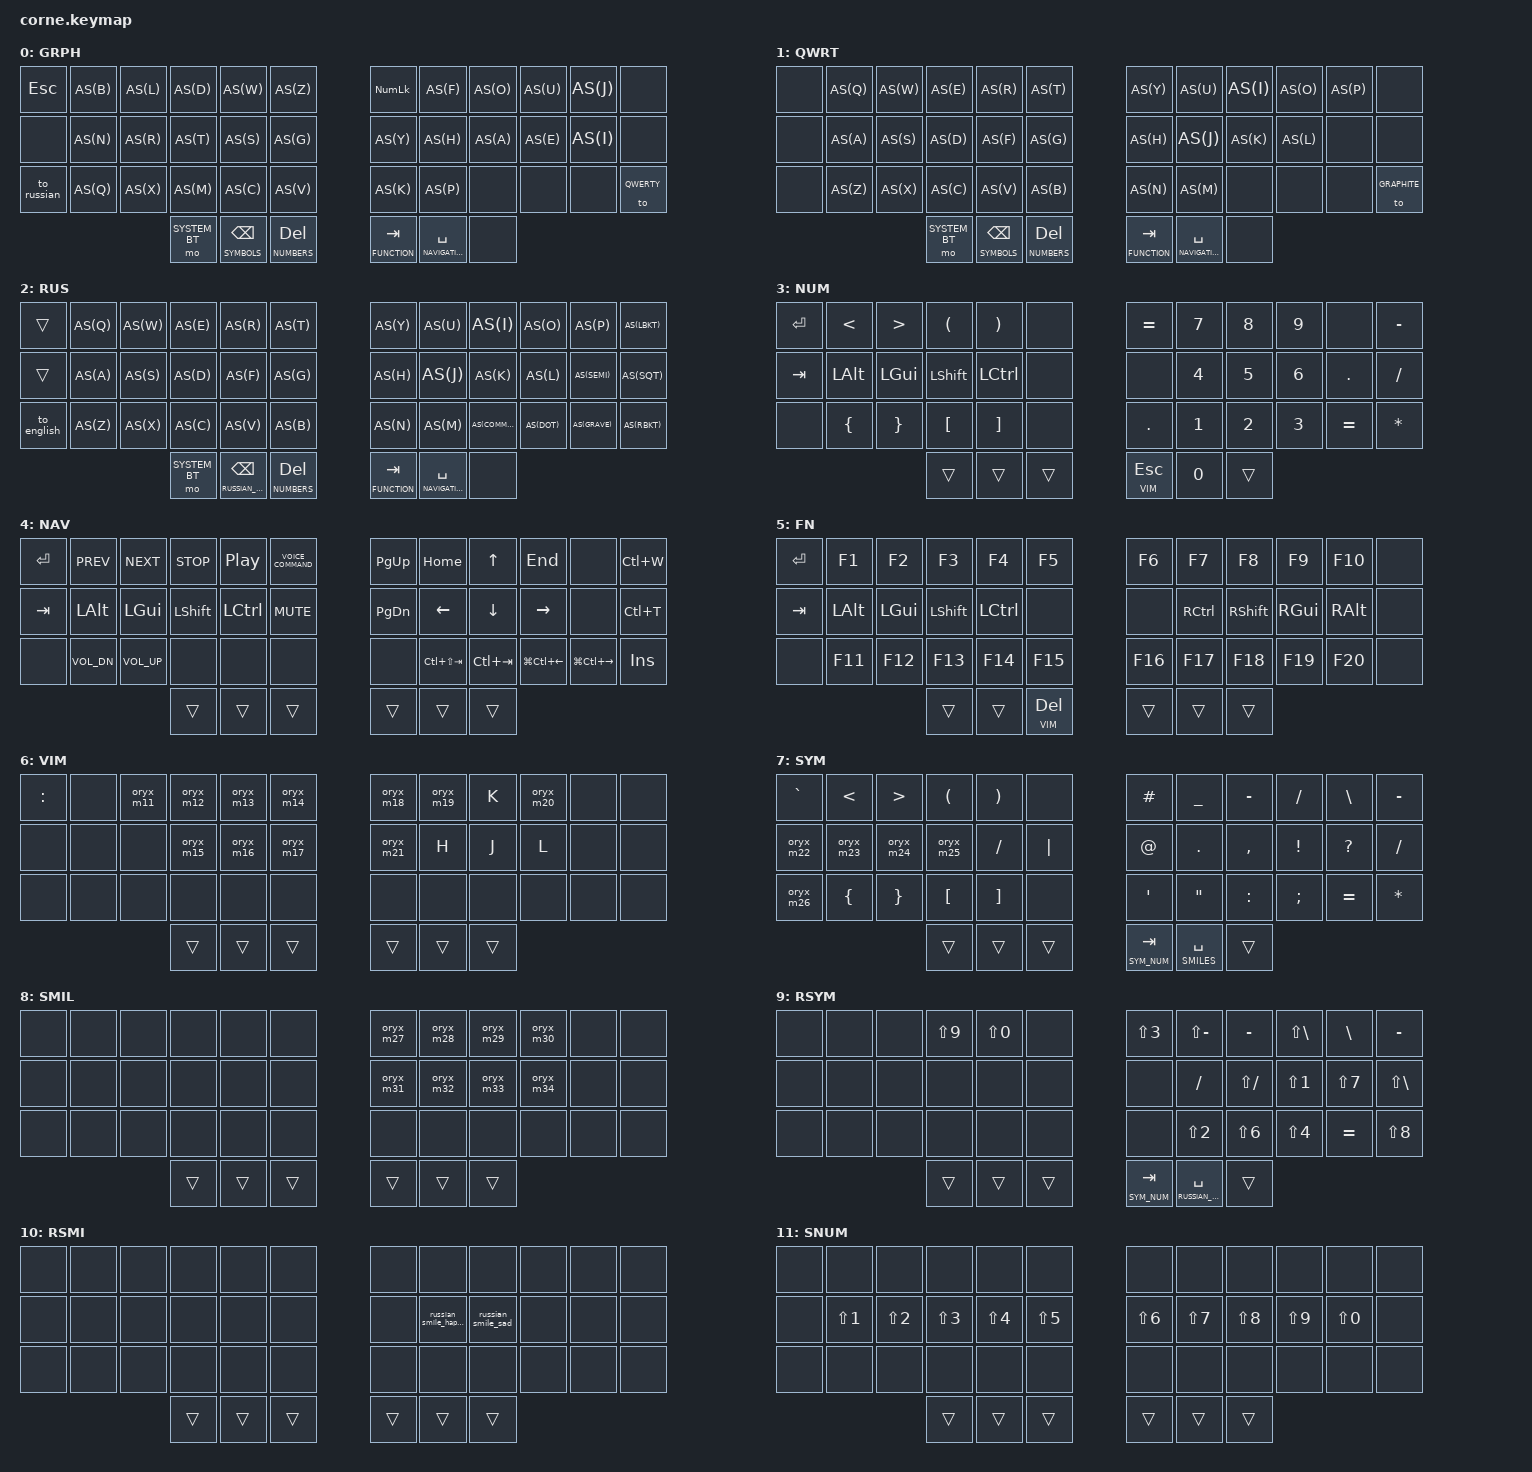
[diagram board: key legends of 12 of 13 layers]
/*
 * Copyright (c) 2020 The ZMK Contributors
 *
 * SPDX-License-Identifier: MIT
 */

#include <behaviors.dtsi>
#include <behaviors/os_profile.dtsi>
#include <dt-bindings/zmk/keys.h>
#include <dt-bindings/zmk/bt.h>
#include <dt-bindings/tpak/os_profile.h>

#define GRAPHITE 0
#define QWERTY 1
#define RUSSIAN 2
#define NUMBERS 3
#define NAVIGATION 4
#define FUNCTION 5
#define VIM 6
#define SYMBOLS 7
#define SMILES 8
#define RUSSIAN_SYMBOLS 9
#define RUSSIAN_SMILES 10
#define SYM_NUM 11
#define SYSTEM_BT 12

// Tap a letter normally; hold it for 300 ms to send Left Shift + letter.
#define AS(keycode) &as LS(keycode) keycode

// Match QMK quick-tap repeat behavior for layer-tap keys.
&lt {
        quick-tap-ms = <250>;
};

// Keep Caps Word active across Russian-PC punctuation-backed letters.
// ZMK only auto-shifts HID A-Z, so RU_HA, RU_HARD, RU_ZHE, RU_E, RU_BE, RU_YU, and RU_YO remain lowercase until a custom behavior is added.
&caps_word {
        continue-list = <UNDERSCORE BACKSPACE DELETE LBKT RBKT SEMI SQT COMMA DOT GRAVE>;
};

/ {
        behaviors {
                as: auto_shift {
                        compatible = "zmk,behavior-hold-tap";
                        #binding-cells = <2>;
                        tapping-term-ms = <300>;
                        quick-tap-ms = <0>;
                        flavor = "tap-preferred";
                        bindings = <&kp>, <&kp>;
                        display-name = "Auto Shift";
                };

                bt_clear_hold: bt_clear_hold {
                        compatible = "zmk,behavior-hold-tap";
                        #binding-cells = <2>;
                        tapping-term-ms = <1500>;
                        quick-tap-ms = <0>;
                        flavor = "tap-preferred";
                        bindings = <&bt_clear_macro>, <&none>;
                        display-name = "Hold to Clear Bluetooth";
                };
        };

        macros {
                // Select Russian-PC on the host with Ctrl+Shift+2, then activate the Russian base layer.
                to_russian: to_russian {
                        compatible = "zmk,behavior-macro";
                        #binding-cells = <0>;
                        wait-ms = <40>;
                        tap-ms = <40>;
                        bindings = <&kp LC(LS(N2)) &to RUSSIAN>;
                };

                // Select English on the host with Ctrl+Shift+1, then return to the Graphite base layer.
                to_english: to_english {
                        compatible = "zmk,behavior-macro";
                        #binding-cells = <0>;
                        wait-ms = <40>;
                        tap-ms = <40>;
                        bindings = <&kp LC(LS(N1)) &to GRAPHITE>;
                };

                // Clears the active Bluetooth profile; invoked only after a protected hold.
                bt_clear_macro: bt_clear_macro {
                        compatible = "zmk,behavior-macro";
                        #binding-cells = <0>;
                        wait-ms = <0>;
                        tap-ms = <0>;
                        bindings = <&bt BT_CLR>;
                };

                // Types "  e" (Space, Space, E).
                oryx_m11: oryx_m11 {
                        compatible = "zmk,behavior-macro";
                        #binding-cells = <0>;
                        wait-ms = <40>;
                        tap-ms = <40>;
                        bindings = <&kp SPACE &kp SPACE &kp E>;
                };

                // Vim: force quit without saving (Esc, :q!, Enter).
                oryx_m12: oryx_m12 {
                        compatible = "zmk,behavior-macro";
                        #binding-cells = <0>;
                        wait-ms = <40>;
                        tap-ms = <40>;
                        bindings = <&kp ESC &kp COLON &kp Q &kp EXCL &kp RET>;
                };

                // Vim: write the current file (Esc, :w, Enter).
                oryx_m13: oryx_m13 {
                        compatible = "zmk,behavior-macro";
                        #binding-cells = <0>;
                        wait-ms = <40>;
                        tap-ms = <40>;
                        bindings = <&kp ESC &kp COLON &kp W &kp RET>;
                };

                // Types " gg" (Space, G, G).
                oryx_m14: oryx_m14 {
                        compatible = "zmk,behavior-macro";
                        #binding-cells = <0>;
                        wait-ms = <40>;
                        tap-ms = <40>;
                        bindings = <&kp SPACE &kp G &kp G>;
                };

                // Vim: quit the current window (Esc, :q, Enter).
                oryx_m15: oryx_m15 {
                        compatible = "zmk,behavior-macro";
                        #binding-cells = <0>;
                        wait-ms = <40>;
                        tap-ms = <40>;
                        bindings = <&kp ESC &kp COLON &kp Q &kp RET>;
                };

                // Vim: write and quit (Esc, :wq, Enter).
                oryx_m16: oryx_m16 {
                        compatible = "zmk,behavior-macro";
                        #binding-cells = <0>;
                        wait-ms = <40>;
                        tap-ms = <40>;
                        bindings = <&kp ESC &kp COLON &kp W &kp Q &kp RET>;
                };

                // Types " tb" (Space, T, B).
                oryx_m17: oryx_m17 {
                        compatible = "zmk,behavior-macro";
                        #binding-cells = <0>;
                        wait-ms = <40>;
                        tap-ms = <40>;
                        bindings = <&kp SPACE &kp T &kp B>;
                };

                // Vim: close the current window (Ctrl-W, q).
                oryx_m18: oryx_m18 {
                        compatible = "zmk,behavior-macro";
                        #binding-cells = <0>;
                        wait-ms = <40>;
                        tap-ms = <40>;
                        bindings = <&kp LC(W) &kp Q>;
                };

                // Vim: create a horizontal split (Esc, :sp, Enter).
                oryx_m19: oryx_m19 {
                        compatible = "zmk,behavior-macro";
                        #binding-cells = <0>;
                        wait-ms = <40>;
                        tap-ms = <40>;
                        bindings = <&kp ESC &kp COLON &kp S &kp P &kp RET>;
                };

                // Vim: create a vertical split (Esc, :vsp, Enter).
                oryx_m20: oryx_m20 {
                        compatible = "zmk,behavior-macro";
                        #binding-cells = <0>;
                        wait-ms = <40>;
                        tap-ms = <40>;
                        bindings = <&kp ESC &kp COLON &kp V &kp S &kp P &kp RET>;
                };

                // Vim: send the window-command prefix (Ctrl-W).
                oryx_m21: oryx_m21 {
                        compatible = "zmk,behavior-macro";
                        #binding-cells = <0>;
                        wait-ms = <40>;
                        tap-ms = <40>;
                        bindings = <&kp LC(W)>;
                };

                // Types ". ~/".
                oryx_m22: oryx_m22 {
                        compatible = "zmk,behavior-macro";
                        #binding-cells = <0>;
                        wait-ms = <40>;
                        tap-ms = <40>;
                        bindings = <&kp DOT &kp SPACE &kp TILDE &kp FSLH>;
                };

                // Types "~/".
                oryx_m23: oryx_m23 {
                        compatible = "zmk,behavior-macro";
                        #binding-cells = <0>;
                        wait-ms = <40>;
                        tap-ms = <40>;
                        bindings = <&kp TILDE &kp FSLH>;
                };

                // Types "../".
                oryx_m24: oryx_m24 {
                        compatible = "zmk,behavior-macro";
                        #binding-cells = <0>;
                        wait-ms = <40>;
                        tap-ms = <40>;
                        bindings = <&kp DOT &kp DOT &kp FSLH>;
                };

                // Types "./".
                oryx_m25: oryx_m25 {
                        compatible = "zmk,behavior-macro";
                        #binding-cells = <0>;
                        wait-ms = <40>;
                        tap-ms = <40>;
                        bindings = <&kp DOT &kp FSLH>;
                };

                // Types ". ./".
                oryx_m26: oryx_m26 {
                        compatible = "zmk,behavior-macro";
                        #binding-cells = <0>;
                        wait-ms = <40>;
                        tap-ms = <40>;
                        bindings = <&kp DOT &kp SPACE &kp DOT &kp FSLH>;
                };

                // Types "8-O".
                oryx_m27: oryx_m27 {
                        compatible = "zmk,behavior-macro";
                        #binding-cells = <0>;
                        wait-ms = <40>;
                        tap-ms = <40>;
                        bindings = <&kp N8 &kp MINUS &kp LS(O)>;
                };

                // Types ":-|".
                oryx_m28: oryx_m28 {
                        compatible = "zmk,behavior-macro";
                        #binding-cells = <0>;
                        wait-ms = <40>;
                        tap-ms = <40>;
                        bindings = <&kp COLON &kp MINUS &kp PIPE>;
                };

                // Types colon, minus, and backslash.
                oryx_m29: oryx_m29 {
                        compatible = "zmk,behavior-macro";
                        #binding-cells = <0>;
                        wait-ms = <40>;
                        tap-ms = <40>;
                        bindings = <&kp COLON &kp MINUS &kp BSLH>;
                };

                // Types ":`[".
                oryx_m30: oryx_m30 {
                        compatible = "zmk,behavior-macro";
                        #binding-cells = <0>;
                        wait-ms = <40>;
                        tap-ms = <40>;
                        bindings = <&kp COLON &kp GRAVE &kp LBKT>;
                };

                // Types ":D".
                oryx_m31: oryx_m31 {
                        compatible = "zmk,behavior-macro";
                        #binding-cells = <0>;
                        wait-ms = <40>;
                        tap-ms = <40>;
                        bindings = <&kp COLON &kp LS(D)>;
                };

                // Types ":)".
                oryx_m32: oryx_m32 {
                        compatible = "zmk,behavior-macro";
                        #binding-cells = <0>;
                        wait-ms = <40>;
                        tap-ms = <40>;
                        bindings = <&kp COLON &kp RPAR>;
                };

                // Types ":(".
                oryx_m33: oryx_m33 {
                        compatible = "zmk,behavior-macro";
                        #binding-cells = <0>;
                        wait-ms = <40>;
                        tap-ms = <40>;
                        bindings = <&kp COLON &kp LPAR>;
                };

                // Types ":-E".
                oryx_m34: oryx_m34 {
                        compatible = "zmk,behavior-macro";
                        #binding-cells = <0>;
                        wait-ms = <40>;
                        tap-ms = <40>;
                        bindings = <&kp COLON &kp MINUS &kp LS(E)>;
                };

                // Russian-PC smile from Oryx ST_MACRO_35: types ":)" with Shift+6, Shift+0.
                russian_smile_happy: russian_smile_happy {
                        compatible = "zmk,behavior-macro";
                        #binding-cells = <0>;
                        wait-ms = <10>;
                        tap-ms = <10>;
                        bindings = <&kp LS(N6) &kp LS(N0)>;
                };

                // Russian-PC sad smile from Oryx ST_MACRO_36: types ":(" with Shift+6, Shift+9.
                russian_smile_sad: russian_smile_sad {
                        compatible = "zmk,behavior-macro";
                        #binding-cells = <0>;
                        wait-ms = <10>;
                        tap-ms = <10>;
                        bindings = <&kp LS(N6) &kp LS(N9)>;
                };
        };

        combos {
                compatible = "zmk,combos";

                // Graphite F+O+U: select Russian-PC on the host and activate the Russian layer.
                to_russian_combo {
                        timeout-ms = <50>;
                        key-positions = <7 8 9>;
                        bindings = <&to_russian>;
                        layers = <GRAPHITE>;
                };

                // Russian RU_GHE+RU_SHA+RU_SHCH: select English on the host and return to Graphite.
                to_english_combo {
                        timeout-ms = <50>;
                        key-positions = <7 8 9>;
                        bindings = <&to_english>;
                        layers = <RUSSIAN>;
                };

                enter_combo {
                        timeout-ms = <50>;
                        key-positions = <19 20 21>;
                        bindings = <&kp RET>;
                        layers = <GRAPHITE QWERTY RUSSIAN>;
                };

                tab_combo {
                        timeout-ms = <50>;
                        key-positions = <14 15 16>;
                        bindings = <&kp TAB>;
                        layers = <GRAPHITE QWERTY RUSSIAN>;
                };

                // Oryx N+S: toggle Caps Word on the base layer.
                caps_word_combo {
                        timeout-ms = <50>;
                        key-positions = <13 16>;
                        bindings = <&caps_word>;
                        layers = <GRAPHITE QWERTY RUSSIAN>;
                };

                // Oryx N+G: toggle Caps Lock on the base layer.
                caps_lock_combo {
                        timeout-ms = <50>;
                        key-positions = <13 17>;
                        bindings = <&kp CAPSLOCK>;
                        layers = <GRAPHITE QWERTY RUSSIAN>;
                };

                // Oryx 7+8+9: type minus on the Numbers layer.
                numbers_minus_combo {
                        timeout-ms = <50>;
                        key-positions = <7 8 9>;
                        bindings = <&kp MINUS>;
                        layers = <NUMBERS>;
                };

                // Oryx 4+5+6: type equals on the Numbers layer.
                numbers_equal_combo {
                        timeout-ms = <50>;
                        key-positions = <19 20 21>;
                        bindings = <&kp EQUAL>;
                        layers = <NUMBERS>;
                };

                // Oryx 1+2+3: type plus on the Numbers layer.
                numbers_plus_combo {
                        timeout-ms = <50>;
                        key-positions = <31 32 33>;
                        bindings = <&kp PLUS>;
                        layers = <NUMBERS>;
                };

                // Oryx 4+5+6+Dot: type slash on the Numbers layer.
                numbers_slash_combo {
                        timeout-ms = <80>;
                        key-positions = <19 20 21 22>;
                        bindings = <&kp FSLH>;
                        layers = <NUMBERS>;
                };

                // Oryx 1+2+3+Equal: type asterisk on the Numbers layer.
                numbers_asterisk_combo {
                        timeout-ms = <80>;
                        key-positions = <31 32 33 34>;
                        bindings = <&kp ASTRK>;
                        layers = <NUMBERS>;
                };

                // Oryx G+Z: hold the English Smiles layer.
                smiles_layer_combo {
                        timeout-ms = <50>;
                        key-positions = <5 17>;
                        bindings = <&mo SMILES>;
                        layers = <GRAPHITE QWERTY>;
                        slow-release;
                };

                // Oryx Russian RU_PE+RU_IE: hold the Russian Smiles layer.
                russian_smiles_layer_combo {
                        timeout-ms = <50>;
                        key-positions = <5 17>;
                        bindings = <&mo RUSSIAN_SMILES>;
                        layers = <RUSSIAN>;
                        slow-release;
                };

                // Oryx H+I: activate the Vim layer for one keypress.
                vim_layer_combo {
                        timeout-ms = <50>;
                        key-positions = <19 22>;
                        bindings = <&sl VIM>;
                        layers = <GRAPHITE QWERTY>;
                };

                // Oryx Q+N: hold Left Alt.
                left_alt_combo {
                        timeout-ms = <50>;
                        key-positions = <13 25>;
                        bindings = <&kp LALT>;
                        layers = <GRAPHITE QWERTY RUSSIAN>;
                        slow-release;
                };

                // Oryx X+R: hold Left GUI.
                left_gui_combo {
                        timeout-ms = <50>;
                        key-positions = <14 26>;
                        bindings = <&kp LGUI>;
                        layers = <GRAPHITE QWERTY RUSSIAN>;
                        slow-release;
                };

                // Oryx M+T: hold Left Shift.
                left_shift_combo {
                        timeout-ms = <50>;
                        key-positions = <15 27>;
                        bindings = <&kp LSHIFT>;
                        layers = <GRAPHITE QWERTY RUSSIAN>;
                        slow-release;
                };

                // Oryx C+S: hold Left Control.
                left_ctrl_combo {
                        timeout-ms = <50>;
                        key-positions = <16 28>;
                        bindings = <&kp LCTRL>;
                        layers = <GRAPHITE QWERTY RUSSIAN>;
                        slow-release;
                };

                // Oryx P+H: hold Right Control.
                right_ctrl_combo {
                        timeout-ms = <50>;
                        key-positions = <19 31>;
                        bindings = <&kp RCTRL>;
                        layers = <GRAPHITE QWERTY RUSSIAN>;
                        slow-release;
                };

                // Oryx F22+A: hold Right Shift.
                right_shift_combo {
                        timeout-ms = <50>;
                        key-positions = <20 32>;
                        bindings = <&kp RSHIFT>;
                        layers = <GRAPHITE QWERTY RUSSIAN>;
                        slow-release;
                };

                // Oryx F23+E: hold Right GUI.
                right_gui_combo {
                        timeout-ms = <50>;
                        key-positions = <21 33>;
                        bindings = <&kp RGUI>;
                        layers = <GRAPHITE QWERTY RUSSIAN>;
                        slow-release;
                };

                // Oryx F24+I: hold Right Alt.
                right_alt_combo {
                        timeout-ms = <50>;
                        key-positions = <22 34>;
                        bindings = <&kp RALT>;
                        layers = <GRAPHITE QWERTY RUSSIAN>;
                        slow-release;
                };

                // Oryx R+L: OS-aware Copy.
                copy_combo {
                        timeout-ms = <50>;
                        key-positions = <2 14>;
                        bindings = <&os_action OS_ACTION_COPY>;
                        layers = <GRAPHITE QWERTY RUSSIAN>;
                };

                // Oryx T+D: OS-aware Paste.
                paste_combo {
                        timeout-ms = <50>;
                        key-positions = <3 15>;
                        bindings = <&os_action OS_ACTION_PASTE>;
                        layers = <GRAPHITE QWERTY RUSSIAN>;
                };

                // Oryx R+L+T+D: OS-aware Cut.
                cut_combo {
                        timeout-ms = <80>;
                        key-positions = <2 3 14 15>;
                        bindings = <&os_action OS_ACTION_CUT>;
                        layers = <GRAPHITE QWERTY RUSSIAN>;
                };

                // Oryx A+O: OS-aware Undo.
                undo_combo {
                        timeout-ms = <50>;
                        key-positions = <8 20>;
                        bindings = <&os_action OS_ACTION_UNDO>;
                        layers = <GRAPHITE QWERTY RUSSIAN>;
                };

                // Oryx E+U: OS-aware Redo.
                redo_combo {
                        timeout-ms = <50>;
                        key-positions = <9 21>;
                        bindings = <&os_action OS_ACTION_REDO>;
                        layers = <GRAPHITE QWERTY RUSSIAN>;
                };

                // Oryx Y+H+A: OS-aware voice command.
                voice_combo {
                        timeout-ms = <50>;
                        key-positions = <18 19 20>;
                        bindings = <&os_action OS_ACTION_VOICE>;
                        layers = <GRAPHITE QWERTY RUSSIAN>;
                };

                // Oryx N+R+T: OS-aware deletion of the previous word.
                word_backspace_combo {
                        timeout-ms = <50>;
                        key-positions = <13 14 15>;
                        bindings = <&os_action OS_ACTION_WORD_BACKSPACE>;
                        layers = <GRAPHITE QWERTY RUSSIAN>;
                };

                // Oryx A+E+I: OS-aware deletion of the next word.
                word_delete_combo {
                        timeout-ms = <50>;
                        key-positions = <20 21 22>;
                        bindings = <&os_action OS_ACTION_WORD_DELETE>;
                        layers = <GRAPHITE QWERTY RUSSIAN>;
                };

                // Oryx Q+X+M: OS-aware movement to the previous word.
                word_previous_combo {
                        timeout-ms = <50>;
                        key-positions = <25 26 27>;
                        bindings = <&os_action OS_ACTION_WORD_PREVIOUS>;
                        layers = <GRAPHITE QWERTY RUSSIAN>;
                };

                // Oryx F22+F23+F24 positions: OS-aware movement to the next word.
                word_next_combo {
                        timeout-ms = <50>;
                        key-positions = <32 33 34>;
                        bindings = <&os_action OS_ACTION_WORD_NEXT>;
                        layers = <GRAPHITE QWERTY RUSSIAN>;
                };

                // Oryx H+A+E+I: OS-aware application switcher.
                app_switch_combo {
                        timeout-ms = <80>;
                        key-positions = <19 20 21 22>;
                        bindings = <&os_action OS_ACTION_APP_SWITCH>;
                        layers = <GRAPHITE QWERTY RUSSIAN>;
                };

                // Oryx N+R+T+S: OS-aware task view.
                task_view_combo {
                        timeout-ms = <80>;
                        key-positions = <13 14 15 16>;
                        bindings = <&os_action OS_ACTION_TASK_VIEW>;
                        layers = <GRAPHITE QWERTY RUSSIAN>;
                };

                // Oryx N+B: OS-aware Select All.
                select_all_combo {
                        timeout-ms = <50>;
                        key-positions = <1 13>;
                        bindings = <&os_action OS_ACTION_SELECT_ALL>;
                        layers = <GRAPHITE QWERTY RUSSIAN>;
                };
        };

        keymap {
                compatible = "zmk,keymap";

                graphite_layer {
// -------------------------------------------------------------------------------------------------
// |  ESC  |  B  |  L  |  D  |  W  |  Z  |   | NUM |  F  |  O  |  U  |  J  |       |
// |       |  N  |  R  |  T  |  S  |  G  |   |  Y  |  H  |  A  |  E  |  I  |       |
// |       |  Q  |  X  |  M  |  C  |  V  |   |  K  |  P  |     |     |     | QWERTY|
//               | SYSTEM | BSP/SYMB | DEL/NUM |   | TAB/FN | SPC/NAV |       |
                        display-name = "GRPH";
                        bindings = <
   &kp ESC AS(B) AS(L) AS(D) AS(W) AS(Z)   &kp KP_NUMLOCK AS(F) AS(O) AS(U) AS(J) &none
   &none AS(N) AS(R) AS(T) AS(S) AS(G)   AS(Y) AS(H) AS(A) AS(E) AS(I) &none
   &to_russian AS(Q) AS(X) AS(M) AS(C) AS(V)   AS(K) AS(P) &none &none &none &to QWERTY
                  &mo SYSTEM_BT &lt SYMBOLS BSPC &lt NUMBERS DEL   &lt FUNCTION TAB &lt NAVIGATION SPACE &none
                        >;
                };

                qwerty_layer {
// -------------------------------------------------------------------------------------------------
// |       |  Q  |  W  |  E  |  R  |  T  |   |  Y  |  U  |  I  |  O  |  P  |       |
// |       |  A  |  S  |  D  |  F  |  G  |   |  H  |  J  |  K  |  L  |     |       |
// |       |  Z  |  X  |  C  |  V  |  B  |   |  N  |  M  |     |     |     |GRAPHITE|
//               | SYSTEM | BSP/SYMB | DEL/NUM |   | TAB/FN | SPC/NAV |       |
                        display-name = "QWRT";
                        bindings = <
   &none AS(Q) AS(W) AS(E) AS(R) AS(T)   AS(Y) AS(U) AS(I) AS(O) AS(P) &none
   &none AS(A) AS(S) AS(D) AS(F) AS(G)   AS(H) AS(J) AS(K) AS(L) &none &none
   &none AS(Z) AS(X) AS(C) AS(V) AS(B)   AS(N) AS(M) &none &none &none &to GRAPHITE
                  &mo SYSTEM_BT &lt SYMBOLS BSPC &lt NUMBERS DEL   &lt FUNCTION TAB &lt NAVIGATION SPACE &none
                        >;
                };

                russian_layer {
// -------------------------------------------------------------------------------------------------
// | ESC* | RU_SHTI | RU_TSE | RU_U | RU_KA | RU_IE | | RU_EN | RU_GHE | RU_SHA | RU_SHCH | RU_ZE | RU_HA |
// |      | RU_EF   | RU_YERU| RU_VE| RU_A  | RU_PE | | RU_ER | RU_O   | RU_EL  | RU_DE   | RU_ZHE| RU_E  |
// | ENG  | RU_YA   | RU_CHE | RU_ES| RU_EM | RU_I  | | RU_TE | RU_SOFT| RU_BE  | RU_YU   | RU_YO | RU_HARD|
//               | SYSTEM | BSP/RU-SYM | DEL/NUM |   | TAB/FN | SPC/NAV |       |
// * position 0 is transparent and inherits Escape from Graphite.
                        display-name = "RUS";
                        bindings = <
   &trans AS(Q) AS(W) AS(E) AS(R) AS(T)   AS(Y) AS(U) AS(I) AS(O) AS(P) AS(LBKT)
   &trans AS(A) AS(S) AS(D) AS(F) AS(G)   AS(H) AS(J) AS(K) AS(L) AS(SEMI) AS(SQT)
   &to_english AS(Z) AS(X) AS(C) AS(V) AS(B)   AS(N) AS(M) AS(COMMA) AS(DOT) AS(GRAVE) AS(RBKT)
                  &mo SYSTEM_BT &lt RUSSIAN_SYMBOLS BSPC &lt NUMBERS DEL   &lt FUNCTION TAB &lt NAVIGATION SPACE &none
                        >;
                };

                numbers_layer {
// -----------------------------------------------------------------------------------------
// | ENT |  <  |  >  |  (  |  )  |     |   |  =  |  7  |  8  |  9  |     |  -  |
// | TAB | ALT | GUI | SHFT| CTRL|     |   |     |  4  |  5  |  6  |  .  |  /  |
// |     |  {  |  }  |  [  |  ]  |     |   |  .  |  1  |  2  |  3  |  =  |  *  |
//                    |     |     |     |   |     |     |     |
                        display-name = "NUM";
                        bindings = <
   &kp RET &kp LESS_THAN &kp GREATER_THAN &kp LPAR &kp RPAR &none   &kp EQUAL &kp N7 &kp N8 &kp N9 &none &kp MINUS
   &kp TAB &kp LALT &kp LGUI &kp LSHFT &kp LCTRL &none              &none &kp N4 &kp N5 &kp N6 &kp DOT &kp FSLH
   &none &kp LBRC &kp RBRC &kp LBKT &kp RBKT &none                  &kp DOT &kp N1 &kp N2 &kp N3 &kp EQUAL &kp ASTRK
                  &trans &trans &trans   &lt VIM ESC &kp N0 &trans
                        >;
                };

                navigation_layer {
// -----------------------------------------------------------------------------------------
// | ENT | PREV | NEXT | STOP | PLAY | VOICE |   | PGUP | HOME |  UP  | END |     | CTRL-W |
// | TAB | LALT | LGUI | LSFT | LCTL | MUTE  |   | PGDN | LEFT | DOWN | RGT |     | CTRL-T |
// |     | VOLD | VOLU |      |      |       |   |      | P-TAB| N-TAB| P-DESK | N-DESK | INS |
//                    |     |     |     |   |     |     |     |
                        display-name = "NAV";
                        bindings = <
   &kp RET &kp C_PREV &kp C_NEXT &kp C_STOP &kp C_PP &kp C_VOICE_COMMAND   &kp PG_UP &kp HOME &kp UP &kp END &none &kp LC(W)
   &kp TAB &kp LALT &kp LGUI &kp LSHFT &kp LCTRL &kp C_MUTE               &kp PG_DN &kp LEFT &kp DOWN &kp RIGHT &none &kp LC(T)
   &none &kp C_VOL_DN &kp C_VOL_UP &none &none &none                      &none &kp LC(LS(TAB)) &kp LC(TAB) &kp LG(LC(LEFT)) &kp LG(LC(RIGHT)) &kp INS
                  &trans &trans &trans   &trans &trans &trans
                        >;
                };

                function_layer {
// -----------------------------------------------------------------------------------------
// | ENT | F1   | F2   | F3   | F4   | F5   |   | F6   | F7   | F8   | F9   | F10  |      |
// | TAB | LALT | LGUI | LSFT | LCTL |      |   |      | RCTL | RSFT | RGUI | RALT |      |
// |     | F11  | F12  | F13  | F14  | F15  |   | F16  | F17  | F18  | F19  | F20  |      |
//                    |     |     |     |   |     |     |     |
                        display-name = "FN";
                        bindings = <
   &kp RET &kp F1 &kp F2 &kp F3 &kp F4 &kp F5                 &kp F6 &kp F7 &kp F8 &kp F9 &kp F10 &none
   &kp TAB &kp LALT &kp LGUI &kp LSHFT &kp LCTRL &none        &none &kp RCTRL &kp RSHFT &kp RGUI &kp RALT &none
   &none &kp F11 &kp F12 &kp F13 &kp F14 &kp F15              &kp F16 &kp F17 &kp F18 &kp F19 &kp F20 &none
                  &trans &trans &lt VIM DEL   &trans &trans &trans
                        >;
                };

                vim_layer {
// -----------------------------------------------------------------------------------------
// |  :  |     | M11 | M12 | M13 | M14 |   | M18 | M19 |  K  | M20 |     |     |
// |     |     |     | M15 | M16 | M17 |   | M21 |  H  |  J  |  L  |     |     |
// |     |     |     |     |     |     |   |     |     |     |     |     |     |
//                    |     |     |     |   |     |     |     |
                        display-name = "VIM";
                        bindings = <
   &kp COLON &none &oryx_m11 &oryx_m12 &oryx_m13 &oryx_m14   &oryx_m18 &oryx_m19 &kp K &oryx_m20 &none &none
   &none &none &none &oryx_m15 &oryx_m16 &oryx_m17           &oryx_m21 &kp H &kp J &kp L &none &none
   &none &none &none &none &none &none                       &none &none &none &none &none &none
                  &trans &trans &trans   &trans &trans &trans
                        >;
                };

                symbols_layer {
// -----------------------------------------------------------------------------------------
// |  `  |  <  |  >  |  (  |  )  |     |   |  #  |  _  |  -  |  /  |  \\  |  -  |
// | M22 | M23 | M24 | M25 |  /  |  |  |   |  @  |  .  |  ,  |  !  |  ?  |  /  |
// | M26 |  {  |  }  |  [  |  ]  |     |   |  '  |  \"  |  :  |  ;  |  =  |  *  |
//                    |     |     |     |   | TAB/SYM-NUM | SPC/SMILES |     |
                        display-name = "SYM";
                        bindings = <
   &kp GRAVE &kp LESS_THAN &kp GREATER_THAN &kp LPAR &kp RPAR &none   &kp HASH &kp UNDER &kp MINUS &kp FSLH &kp BSLH &kp MINUS
   &oryx_m22 &oryx_m23 &oryx_m24 &oryx_m25 &kp FSLH &kp PIPE         &kp AT &kp DOT &kp COMMA &kp EXCL &kp QMARK &kp FSLH
   &oryx_m26 &kp LBRC &kp RBRC &kp LBKT &kp RBKT &none               &kp SQT &kp DQT &kp COLON &kp SEMI &kp EQUAL &kp ASTRK
                  &trans &trans &trans   &lt SYM_NUM TAB &lt SMILES SPACE &trans
                        >;
                };

                smiles_layer {
// -----------------------------------------------------------------------------------------
// |     |     |     |     |     |     |   | M27 | M28 | M29 | M30 |     |     |
// |     |     |     |     |     |     |   | M31 | M32 | M33 | M34 |     |     |
// |     |     |     |     |     |     |   |     |     |     |     |     |     |
//                    |     |     |     |   |     |     |     |
                        display-name = "SMIL";
                        bindings = <
   &none &none &none &none &none &none   &oryx_m27 &oryx_m28 &oryx_m29 &oryx_m30 &none &none
   &none &none &none &none &none &none   &oryx_m31 &oryx_m32 &oryx_m33 &oryx_m34 &none &none
   &none &none &none &none &none &none   &none &none &none &none &none &none
                  &trans &trans &trans   &trans &trans &trans
                        >;
                };

                russian_symbols_layer {
// -------------------------------------------------------------------------------------------------
// |     |     |     |  (  |  )  |     |   |  №  |  _  |  -  |  /  |  \\  |  -  |
// |     |     |     |     |     |     |   |     |  .  |  ,  |  !  |  ?  |  /  |
// |     |     |     |     |     |     |   |     |  "  |  :  |  ;  |  =  |  *  |
//                    |     |     |     |   | TAB/SYM-NUM | SPC/RU-SMILES |     |
// Bindings preserve QMK HID usages and rely on Russian-PC on the host.
                        display-name = "RSYM";
                        bindings = <
   &none &none &none &kp LS(N9) &kp LS(N0) &none   &kp LS(N3) &kp LS(MINUS) &kp MINUS &kp LS(BSLH) &kp BSLH &kp MINUS
   &none &none &none &none &none &none              &none &kp FSLH &kp LS(FSLH) &kp LS(N1) &kp LS(N7) &kp LS(BSLH)
   &none &none &none &none &none &none              &none &kp LS(N2) &kp LS(N6) &kp LS(N4) &kp EQUAL &kp LS(N8)
                  &trans &trans &trans   &lt SYM_NUM TAB &lt RUSSIAN_SMILES SPACE &trans
                        >;
                };

                russian_smiles_layer {
// -------------------------------------------------------------------------------------------------
// |     |     |     |     |     |     |   |     |     |     |     |     |     |
// |     |     |     |     |     |     |   |     |  :) |  :( |     |     |     |
// |     |     |     |     |     |     |   |     |     |     |     |     |     |
//                    |     |     |     |   |     |     |     |
                        display-name = "RSMI";
                        bindings = <
   &none &none &none &none &none &none   &none &none &none &none &none &none
   &none &none &none &none &none &none   &none &russian_smile_happy &russian_smile_sad &none &none &none
   &none &none &none &none &none &none   &none &none &none &none &none &none
                  &trans &trans &trans   &trans &trans &trans
                        >;
                };

                sym_num_layer {
// -------------------------------------------------------------------------------------------------
// |     |     |     |     |     |     |   |     |     |     |     |     |     |
// |     | S+1 | S+2 | S+3 | S+4 | S+5 |   | S+6 | S+7 | S+8 | S+9 | S+0 |     |
// |     |     |     |     |     |     |   |     |     |     |     |     |     |
//                    |     |     |     |   |     |     |     |
                        display-name = "SNUM";
                        bindings = <
   &none &none &none &none &none &none   &none &none &none &none &none &none
   &none &kp LS(N1) &kp LS(N2) &kp LS(N3) &kp LS(N4) &kp LS(N5)   &kp LS(N6) &kp LS(N7) &kp LS(N8) &kp LS(N9) &kp LS(N0) &none
   &none &none &none &none &none &none   &none &none &none &none &none &none
                  &trans &trans &trans   &trans &trans &trans
                        >;
                };

                system_layer {
// -------------------------------------------------------------------------------------------------
// | BT0 | BT1 | BT2 | BT3 | BT4 |     |   |         |       |       |     |     |     |
// |     |     |     |     |     |     |   |         | WINDOWS | MACOS | LINUX |     |     |
// | CLEAR(hold 1500 ms)    |     |     |   |         |       |       |     |     |     |
//                           |     |     |   |         |       |       |
                        display-name = "SYS";
                        bindings = <
   &bt BT_SEL 0 &bt BT_SEL 1 &bt BT_SEL 2 &bt BT_SEL 3 &bt BT_SEL 4 &none   &none &none &none &none &none &none
   &none &none &none &none &none &none                                          &none &os_set OS_WINDOWS &os_set OS_MACOS &os_set OS_LINUX &none &none
   &bt_clear_hold 0 0 &none &none &none &none &none                             &none &none &none &none &none &none
                  &trans &trans &trans   &trans &trans &trans
                        >;
                };
        };
};
